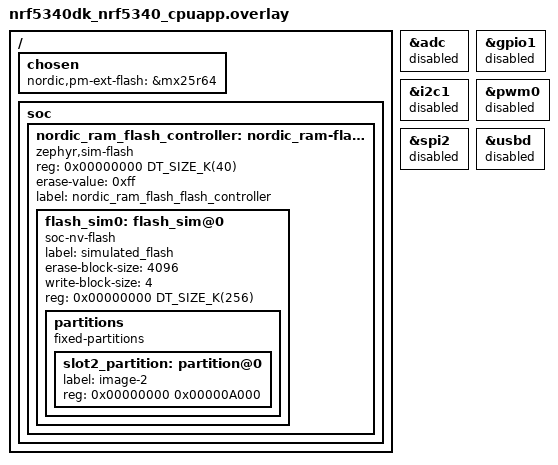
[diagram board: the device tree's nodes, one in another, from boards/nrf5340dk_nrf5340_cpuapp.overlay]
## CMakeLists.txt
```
#
# Copyright (c) 2021 Nordic Semiconductor ASA
#
# SPDX-License-Identifier: LicenseRef-Nordic-5-Clause
#

cmake_minimum_required(VERSION 3.20.0)

if(BOARD STREQUAL "nrf52840dk_nrf52840" OR BOARD STREQUAL "nrf5340dk_nrf5340_cpuapp")
    set(BUILD_WITH_DFU "MATTER" CACHE STRING "Build target with Device Firmware Upgrade support")
else()
    set(BUILD_WITH_DFU "OFF" CACHE STRING "Build target with Device Firmware Upgrade support")
endif()

if(NOT BUILD_WITH_DFU STREQUAL "OFF")
    if(BUILD_WITH_DFU STREQUAL "BLE" AND BOARD STREQUAL "nrf5340dk_nrf5340_cpuapp")
        set(CONF_FILE prj_multi_image_smp_dfu.conf)
    elseif(BUILD_WITH_DFU STREQUAL "BLE")
        set(CONF_FILE prj_single_image_smp_dfu.conf)
    elseif(BUILD_WITH_DFU STREQUAL "MATTER" AND BOARD STREQUAL "nrf5340dk_nrf5340_cpuapp")
        set(CONF_FILE prj_multi_image_matter_dfu.conf)
    elseif(BUILD_WITH_DFU STREQUAL "MATTER")
        set(CONF_FILE prj_single_image_matter_dfu.conf)
    else()
        message(FATAL_ERROR "Selected invalid BUILD_WITH_DFU value: ${BUILD_WITH_DFU}")
    endif()

    if (EXISTS "${CMAKE_CURRENT_SOURCE_DIR}/configuration/${BOARD}/pm_static.yml")
        set(PM_STATIC_YML_FILE ${CMAKE_CURRENT_SOURCE_DIR}/configuration/${BOARD}/pm_static.yml)
    else()
        message(FATAL_ERROR "The ${BOARD} target does not support DFU")
    endif()
endif()

find_package(Zephyr HINTS $ENV{ZEPHYR_BASE})

project(matter-lock)

set(COMMON_ROOT ${ZEPHYR_NRF_MODULE_DIR}/samples/matter/common)
set(NLIO_ROOT ${ZEPHYR_CONNECTEDHOMEIP_MODULE_DIR}/third_party/nlio/repo)
include(${ZEPHYR_CONNECTEDHOMEIP_MODULE_DIR}/config/nrfconnect/app/enable-gnu-std.cmake)
include(${ZEPHYR_CONNECTEDHOMEIP_MODULE_DIR}/src/app/chip_data_model.cmake)

# NORDIC SDK APP START
target_include_directories(app PRIVATE
    src
    ${COMMON_ROOT}/src
    ${NLIO_ROOT}/include
    ${ZEPHYR_CONNECTEDHOMEIP_MODULE_DIR}/zzz_generated/app-common
)

target_sources(app PRIVATE
    src/app_task.cpp
    src/bolt_lock_manager.cpp
    src/main.cpp
    src/zcl_callbacks.cpp
    src/zap-generated/IMClusterCommandHandler.cpp
    src/zap-generated/callback-stub.cpp
    ${COMMON_ROOT}/src/led_widget.cpp
    ${COMMON_ROOT}/src/thread_util.cpp
)

if(BUILD_WITH_DFU STREQUAL "BLE")
    target_sources(app PRIVATE ${COMMON_ROOT}/src/dfu_over_smp.cpp)
endif()

chip_configure_data_model(app
    INCLUDE_SERVER
    ZAP_FILE ${CMAKE_CURRENT_SOURCE_DIR}/src/lock.zap
)
# NORDIC SDK APP END
```

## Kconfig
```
#
# Copyright (c) 2021 Nordic Semiconductor
#
# SPDX-License-Identifier: LicenseRef-Nordic-5-Clause
#

mainmenu "Matter Lock sample application"

config STATE_LEDS
	bool "Use LEDs to indicate the device state"
	default y
	help
	  Use LEDs to render the current state of the device such as the progress of commissioning of
	  the device into a network or the factory reset initiation. Note that setting this option to
	  'n' does not disable the LED indicating the state of the simulated bolt.

source "Kconfig.zephyr"
```

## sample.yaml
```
sample:
  name: Matter Lock
  description: Matter Lock example
tests:
  matter.lock:
    build_only: true
    platform_allow: nrf52840dk_nrf52840 nrf5340dk_nrf5340_cpuapp nrf21540dk_nrf52840
    integration_platforms:
      - nrf52840dk_nrf52840
      - nrf5340dk_nrf5340_cpuapp
      - nrf21540dk_nrf52840
    tags: ci_build
  matter.lock.smp_dfu:
    build_only: true
    platform_allow: nrf52840dk_nrf52840 nrf5340dk_nrf5340_cpuapp
    integration_platforms:
      - nrf52840dk_nrf52840
      - nrf5340dk_nrf5340_cpuapp
    tags: ci_build
    extra_args: "BUILD_WITH_DFU=BLE"
  matter.lock.low_power:
    build_only: true
    platform_allow: nrf52840dk_nrf52840 nrf5340dk_nrf5340_cpuapp
    integration_platforms:
      - nrf52840dk_nrf52840
      - nrf5340dk_nrf5340_cpuapp
    tags: ci_build
    extra_args: "OVERLAY_CONFIG=overlay-low_power.conf"
```

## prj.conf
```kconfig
#
# Copyright (c) 2021 Nordic Semiconductor ASA
#
# SPDX-License-Identifier: LicenseRef-Nordic-5-Clause
#

# Enable CHIP
CONFIG_CHIP=y
CONFIG_CHIP_PROJECT_CONFIG="src/chip_project_config.h"
CONFIG_STD_CPP14=y

# General networking settings
CONFIG_NETWORKING=y
CONFIG_NET_IPV6_NBR_CACHE=n
CONFIG_NET_IPV6_MLD=n
CONFIG_NET_SOCKETS_POLL_MAX=5

# Enable OpenThread MTD
CONFIG_NET_L2_OPENTHREAD=y

CONFIG_OPENTHREAD_MTD=y
CONFIG_OPENTHREAD_FTD=n
CONFIG_OPENTHREAD_SLAAC=y
CONFIG_OPENTHREAD_MTD_NETDIAG=y
CONFIG_OPENTHREAD_MANUAL_START=y
CONFIG_OPENTHREAD_THREAD_STACK_SIZE=6144
CONFIG_OPENTHREAD_NUM_MESSAGE_BUFFERS=64

CONFIG_OPENTHREAD_PANID=4660
CONFIG_OPENTHREAD_CHANNEL=15
CONFIG_OPENTHREAD_NETWORK_NAME="OpenThread"
CONFIG_OPENTHREAD_XPANID="11:11:11:11:22:22:22:22"

# Enable Thread 1.2 features
CONFIG_OPENTHREAD_THREAD_VERSION_1_2=y
CONFIG_OPENTHREAD_DUA=y
CONFIG_OPENTHREAD_MLR=y

# Enable Bluetooth Low Energy
CONFIG_BT=y
CONFIG_BT_PERIPHERAL=y
CONFIG_BT_PERIPHERAL_PREF_MIN_INT=12
CONFIG_BT_PERIPHERAL_PREF_MAX_INT=12
CONFIG_BT_GAP_AUTO_UPDATE_CONN_PARAMS=y
CONFIG_BT_GATT_DYNAMIC_DB=y
CONFIG_BT_DEVICE_APPEARANCE=0
CONFIG_BT_DEVICE_NAME_DYNAMIC=y
CONFIG_BT_DEVICE_NAME_MAX=15
CONFIG_BT_DEVICE_NAME="MatterLock"
CONFIG_BT_MAX_CONN=1
CONFIG_BT_L2CAP_TX_MTU=247
CONFIG_BT_BUF_ACL_RX_SIZE=251
CONFIG_BT_BUF_ACL_TX_SIZE=251

# Use NFC to share commissioning information
CONFIG_CHIP_NFC_COMMISSIONING=y

# Use nrf_security
CONFIG_OPENTHREAD_NRF_SECURITY_CHOICE=y

CONFIG_CC3XX_BACKEND=n
CONFIG_OBERON_BACKEND=y

CONFIG_MBEDTLS_ENABLE_HEAP=y
CONFIG_MBEDTLS_HEAP_SIZE=15360
CONFIG_MBEDTLS_TLS_LIBRARY=y
CONFIG_NRF_SECURITY_ADVANCED=y

CONFIG_MBEDTLS_AES_C=y
CONFIG_MBEDTLS_ECP_C=y
CONFIG_MBEDTLS_ECP_DP_SECP256R1_ENABLED=y
CONFIG_MBEDTLS_CTR_DRBG_C=y
CONFIG_MBEDTLS_CIPHER_MODE_CTR=y
CONFIG_MBEDTLS_ECJPAKE_C=y
CONFIG_MBEDTLS_SHA256_C=y
CONFIG_MBEDTLS_PK_C=y
CONFIG_MBEDTLS_PK_WRITE_C=y
CONFIG_MBEDTLS_X509_CREATE_C=y
CONFIG_MBEDTLS_X509_CSR_WRITE_C=y

# Disable unneeded crypto operations
CONFIG_MBEDTLS_SHA384_C=n
CONFIG_MBEDTLS_SHA512_C=n
CONFIG_MBEDTLS_CIPHER_MODE_XTS=n
CONFIG_MBEDTLS_CHACHA20_C=n
CONFIG_MBEDTLS_POLY1305_C=n
CONFIG_MBEDTLS_CHACHAPOLY_C=n
CONFIG_MBEDTLS_GCM_C=n
CONFIG_MBEDTLS_RSA_C=n

# Add support for LEDs and buttons on Nordic development kits
CONFIG_DK_LIBRARY=y

# Other settings
CONFIG_LOG=y
CONFIG_LOG_MODE_MINIMAL=y
CONFIG_MATTER_LOG_LEVEL_DBG=y
CONFIG_PRINTK_SYNC=y
CONFIG_MAIN_STACK_SIZE=8192
CONFIG_INIT_STACKS=y
CONFIG_HW_STACK_PROTECTION=y
CONFIG_HWINFO=y
CONFIG_THREAD_NAME=y
CONFIG_SHELL=y
CONFIG_ASSERT=y
```

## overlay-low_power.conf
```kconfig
#
# Copyright (c) 2021 Nordic Semiconductor
#
# SPDX-License-Identifier: LicenseRef-Nordic-5-Clause
#

# Enable MTD Sleepy End Device
CONFIG_CHIP_ENABLE_SLEEPY_END_DEVICE_SUPPORT=y

# SED requires less aggresive BLE connection intervals
CONFIG_BT_PERIPHERAL_PREF_MIN_INT=36
CONFIG_BT_PERIPHERAL_PREF_MAX_INT=36

# Disable UART console
CONFIG_SHELL=n
CONFIG_LOG=n
CONFIG_UART_CONSOLE=n
CONFIG_SERIAL=n

# Suspend devices when the CPU goes into sleep
CONFIG_PM_DEVICE=y

# Disable auxiliary state LEDs
CONFIG_STATE_LEDS=n
```

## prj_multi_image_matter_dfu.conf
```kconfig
#
# Copyright (c) 2022 Nordic Semiconductor ASA
#
# SPDX-License-Identifier: LicenseRef-Nordic-5-Clause
#

# Enable CHIP
CONFIG_CHIP=y
CONFIG_CHIP_PROJECT_CONFIG="src/chip_project_config.h"
CONFIG_STD_CPP14=y

# General networking settings
CONFIG_NETWORKING=y
CONFIG_NET_IPV6_NBR_CACHE=n
CONFIG_NET_IPV6_MLD=n
CONFIG_NET_SOCKETS_POLL_MAX=5

# Enable OpenThread MTD
CONFIG_NET_L2_OPENTHREAD=y

CONFIG_OPENTHREAD_MTD=y
CONFIG_OPENTHREAD_FTD=n
CONFIG_OPENTHREAD_SLAAC=y
CONFIG_OPENTHREAD_MTD_NETDIAG=y
CONFIG_OPENTHREAD_MANUAL_START=y
CONFIG_OPENTHREAD_THREAD_STACK_SIZE=6144
CONFIG_OPENTHREAD_NUM_MESSAGE_BUFFERS=64

CONFIG_OPENTHREAD_PANID=4660
CONFIG_OPENTHREAD_CHANNEL=15
CONFIG_OPENTHREAD_NETWORK_NAME="OpenThread"
CONFIG_OPENTHREAD_XPANID="11:11:11:11:22:22:22:22"

# Enable Thread 1.2 features
CONFIG_OPENTHREAD_THREAD_VERSION_1_2=y
CONFIG_OPENTHREAD_DUA=y
CONFIG_OPENTHREAD_MLR=y

# Enable Bluetooth Low Energy
CONFIG_BT=y
CONFIG_BT_PERIPHERAL=y
CONFIG_BT_PERIPHERAL_PREF_MIN_INT=12
CONFIG_BT_PERIPHERAL_PREF_MAX_INT=12
CONFIG_BT_GAP_AUTO_UPDATE_CONN_PARAMS=y
CONFIG_BT_GATT_DYNAMIC_DB=y
CONFIG_BT_DEVICE_APPEARANCE=0
CONFIG_BT_DEVICE_NAME_DYNAMIC=y
CONFIG_BT_DEVICE_NAME_MAX=15
CONFIG_BT_DEVICE_NAME="MatterLock"
CONFIG_BT_MAX_CONN=1
CONFIG_BT_L2CAP_TX_MTU=247
CONFIG_BT_BUF_ACL_RX_SIZE=251
CONFIG_BT_BUF_ACL_TX_SIZE=251

# Use NFC to share commissioning information
CONFIG_CHIP_NFC_COMMISSIONING=y

# Use nrf_security
CONFIG_OPENTHREAD_NRF_SECURITY_CHOICE=y

CONFIG_CC3XX_BACKEND=n
CONFIG_OBERON_BACKEND=y

CONFIG_MBEDTLS_ENABLE_HEAP=y
CONFIG_MBEDTLS_HEAP_SIZE=15360
CONFIG_MBEDTLS_TLS_LIBRARY=y
CONFIG_NRF_SECURITY_ADVANCED=y

CONFIG_MBEDTLS_AES_C=y
CONFIG_MBEDTLS_ECP_C=y
CONFIG_MBEDTLS_ECP_DP_SECP256R1_ENABLED=y
CONFIG_MBEDTLS_CTR_DRBG_C=y
CONFIG_MBEDTLS_CIPHER_MODE_CTR=y
CONFIG_MBEDTLS_ECJPAKE_C=y
CONFIG_MBEDTLS_SHA256_C=y
CONFIG_MBEDTLS_PK_C=y
CONFIG_MBEDTLS_PK_WRITE_C=y
CONFIG_MBEDTLS_X509_CREATE_C=y
CONFIG_MBEDTLS_X509_CSR_WRITE_C=y

# Disable unneeded crypto operations
CONFIG_MBEDTLS_SHA384_C=n
CONFIG_MBEDTLS_SHA512_C=n
CONFIG_MBEDTLS_CIPHER_MODE_XTS=n
CONFIG_MBEDTLS_CHACHA20_C=n
CONFIG_MBEDTLS_POLY1305_C=n
CONFIG_MBEDTLS_CHACHAPOLY_C=n
CONFIG_MBEDTLS_GCM_C=n
CONFIG_MBEDTLS_RSA_C=n

# Add support for LEDs and buttons on Nordic development kits
CONFIG_DK_LIBRARY=y

# Other settings
CONFIG_LOG=y
CONFIG_LOG_MODE_MINIMAL=y
CONFIG_MATTER_LOG_LEVEL_DBG=y
CONFIG_PRINTK_SYNC=y
CONFIG_MAIN_STACK_SIZE=8192
CONFIG_INIT_STACKS=y
CONFIG_HW_STACK_PROTECTION=y
CONFIG_HWINFO=y
CONFIG_THREAD_NAME=y
CONFIG_SHELL=y
CONFIG_ASSERT=y

# Enable bootloader and DFU related configs
CONFIG_BOOTLOADER_MCUBOOT=y
CONFIG_UPDATEABLE_IMAGE_NUMBER=2

# QSPI configuration
CONFIG_NORDIC_QSPI_NOR=y
CONFIG_NORDIC_QSPI_NOR_FLASH_LAYOUT_PAGE_SIZE=4096
CONFIG_NORDIC_QSPI_NOR_STACK_WRITE_BUFFER_SIZE=16

# FLASH nop device is needed to access network core image data.
CONFIG_FLASH_NOP_DEVICE=y

# Enable Matter OTA
CONFIG_CHIP_OTA_REQUESTOR=y
CONFIG_IMG_MANAGER=y
```

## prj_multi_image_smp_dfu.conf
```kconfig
#
# Copyright (c) 2021 Nordic Semiconductor ASA
#
# SPDX-License-Identifier: LicenseRef-Nordic-5-Clause
#

# Enable CHIP
CONFIG_CHIP=y
CONFIG_CHIP_PROJECT_CONFIG="src/chip_project_config.h"
CONFIG_STD_CPP14=y

# General networking settings
CONFIG_NETWORKING=y
CONFIG_NET_IPV6_NBR_CACHE=n
CONFIG_NET_IPV6_MLD=n
CONFIG_NET_SOCKETS_POLL_MAX=5

# Enable OpenThread MTD
CONFIG_NET_L2_OPENTHREAD=y

CONFIG_OPENTHREAD_MTD=y
CONFIG_OPENTHREAD_FTD=n
CONFIG_OPENTHREAD_SLAAC=y
CONFIG_OPENTHREAD_MTD_NETDIAG=y
CONFIG_OPENTHREAD_MANUAL_START=y
CONFIG_OPENTHREAD_THREAD_STACK_SIZE=6144
CONFIG_OPENTHREAD_NUM_MESSAGE_BUFFERS=64

CONFIG_OPENTHREAD_PANID=4660
CONFIG_OPENTHREAD_CHANNEL=15
CONFIG_OPENTHREAD_NETWORK_NAME="OpenThread"
CONFIG_OPENTHREAD_XPANID="11:11:11:11:22:22:22:22"

# Enable Thread 1.2 features
CONFIG_OPENTHREAD_THREAD_VERSION_1_2=y
CONFIG_OPENTHREAD_DUA=y
CONFIG_OPENTHREAD_MLR=y

# Enable Bluetooth Low Energy
CONFIG_BT=y
CONFIG_BT_PERIPHERAL=y
CONFIG_BT_PERIPHERAL_PREF_MIN_INT=12
CONFIG_BT_PERIPHERAL_PREF_MAX_INT=12
CONFIG_BT_GAP_AUTO_UPDATE_CONN_PARAMS=y
CONFIG_BT_GATT_DYNAMIC_DB=y
CONFIG_BT_DEVICE_APPEARANCE=0
CONFIG_BT_DEVICE_NAME_DYNAMIC=y
CONFIG_BT_DEVICE_NAME_MAX=15
CONFIG_BT_DEVICE_NAME="MatterLock"
CONFIG_BT_MAX_CONN=1

# Use NFC to share commissioning information
CONFIG_CHIP_NFC_COMMISSIONING=y

# Use nrf_security
CONFIG_OPENTHREAD_NRF_SECURITY_CHOICE=y

CONFIG_CC3XX_BACKEND=n
CONFIG_OBERON_BACKEND=y

CONFIG_MBEDTLS_ENABLE_HEAP=y
CONFIG_MBEDTLS_HEAP_SIZE=15360
CONFIG_MBEDTLS_TLS_LIBRARY=y
CONFIG_NRF_SECURITY_ADVANCED=y

CONFIG_MBEDTLS_AES_C=y
CONFIG_MBEDTLS_ECP_C=y
CONFIG_MBEDTLS_ECP_DP_SECP256R1_ENABLED=y
CONFIG_MBEDTLS_CTR_DRBG_C=y
CONFIG_MBEDTLS_CIPHER_MODE_CTR=y
CONFIG_MBEDTLS_ECJPAKE_C=y
CONFIG_MBEDTLS_SHA256_C=y
CONFIG_MBEDTLS_PK_C=y
CONFIG_MBEDTLS_PK_WRITE_C=y
CONFIG_MBEDTLS_X509_CREATE_C=y
CONFIG_MBEDTLS_X509_CSR_WRITE_C=y

# Disable unneeded crypto operations
CONFIG_MBEDTLS_SHA384_C=n
CONFIG_MBEDTLS_SHA512_C=n
CONFIG_MBEDTLS_CIPHER_MODE_XTS=n
CONFIG_MBEDTLS_CHACHA20_C=n
CONFIG_MBEDTLS_POLY1305_C=n
CONFIG_MBEDTLS_CHACHAPOLY_C=n
CONFIG_MBEDTLS_GCM_C=n
CONFIG_MBEDTLS_RSA_C=n

# Add support for LEDs and buttons on Nordic development kits
CONFIG_DK_LIBRARY=y

# Other settings
CONFIG_LOG=y
CONFIG_LOG_MODE_MINIMAL=y
CONFIG_MATTER_LOG_LEVEL_DBG=y
CONFIG_PRINTK_SYNC=y
CONFIG_MAIN_STACK_SIZE=8192
CONFIG_INIT_STACKS=y
CONFIG_HW_STACK_PROTECTION=y
CONFIG_HWINFO=y
CONFIG_THREAD_NAME=y
CONFIG_SHELL=y
CONFIG_ASSERT=y

# Enable bootloader and DFU related configs
CONFIG_BOOTLOADER_MCUBOOT=y
CONFIG_UPDATEABLE_IMAGE_NUMBER=2

# QSPI configuration
CONFIG_NORDIC_QSPI_NOR=y
CONFIG_NORDIC_QSPI_NOR_FLASH_LAYOUT_PAGE_SIZE=4096
CONFIG_NORDIC_QSPI_NOR_STACK_WRITE_BUFFER_SIZE=16

# MCU Manager and SMP configuration
CONFIG_MCUMGR=y
CONFIG_MCUMGR_CMD_IMG_MGMT=y
CONFIG_MCUMGR_CMD_OS_MGMT=y
CONFIG_MCUMGR_SMP_BT=y
CONFIG_MCUMGR_SMP_BT_AUTHEN=n
CONFIG_MCUMGR_BUF_COUNT=6

# Increase BT MTU and RX buffer for big size DFU messages
CONFIG_BT_L2CAP_TX_MTU=498
CONFIG_BT_BUF_ACL_TX_SIZE=251
CONFIG_BT_BUF_ACL_RX_SIZE=502

# Increase max number of pending GATT notification callbacks
CONFIG_BT_CONN_TX_MAX=6

# Increase system workqueue size, as SMP is processed within it
CONFIG_SYSTEM_WORKQUEUE_STACK_SIZE=2800

# FLASH nop device is enabled to prevent bus faults when mcumgr tries to access
# simulated partition with network core image data.
CONFIG_FLASH_NOP_DEVICE=y

# Enable custom SMP request to erase settings partition.
CONFIG_MCUMGR_GRP_ZEPHYR_BASIC=y
CONFIG_MCUMGR_GRP_BASIC_CMD_STORAGE_ERASE=y

# Enable Matter OTA
CONFIG_CHIP_OTA_REQUESTOR=y
```

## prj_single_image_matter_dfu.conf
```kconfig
#
# Copyright (c) 2022 Nordic Semiconductor ASA
#
# SPDX-License-Identifier: LicenseRef-Nordic-5-Clause
#

# Enable CHIP
CONFIG_CHIP=y
CONFIG_CHIP_PROJECT_CONFIG="src/chip_project_config.h"
CONFIG_STD_CPP14=y

# General networking settings
CONFIG_NETWORKING=y
CONFIG_NET_IPV6_NBR_CACHE=n
CONFIG_NET_IPV6_MLD=n
CONFIG_NET_SOCKETS_POLL_MAX=5

# Enable OpenThread MTD
CONFIG_NET_L2_OPENTHREAD=y

CONFIG_OPENTHREAD_MTD=y
CONFIG_OPENTHREAD_FTD=n
CONFIG_OPENTHREAD_SLAAC=y
CONFIG_OPENTHREAD_MTD_NETDIAG=y
CONFIG_OPENTHREAD_MANUAL_START=y
CONFIG_OPENTHREAD_THREAD_STACK_SIZE=6144
CONFIG_OPENTHREAD_NUM_MESSAGE_BUFFERS=64

CONFIG_OPENTHREAD_PANID=4660
CONFIG_OPENTHREAD_CHANNEL=15
CONFIG_OPENTHREAD_NETWORK_NAME="OpenThread"
CONFIG_OPENTHREAD_XPANID="11:11:11:11:22:22:22:22"

# Enable Thread 1.2 features
CONFIG_OPENTHREAD_THREAD_VERSION_1_2=y
CONFIG_OPENTHREAD_DUA=y
CONFIG_OPENTHREAD_MLR=y

# Enable Bluetooth Low Energy
CONFIG_BT=y
CONFIG_BT_PERIPHERAL=y
CONFIG_BT_PERIPHERAL_PREF_MIN_INT=12
CONFIG_BT_PERIPHERAL_PREF_MAX_INT=12
CONFIG_BT_GAP_AUTO_UPDATE_CONN_PARAMS=y
CONFIG_BT_GATT_DYNAMIC_DB=y
CONFIG_BT_DEVICE_APPEARANCE=0
CONFIG_BT_DEVICE_NAME_DYNAMIC=y
CONFIG_BT_DEVICE_NAME_MAX=15
CONFIG_BT_DEVICE_NAME="MatterLock"
CONFIG_BT_MAX_CONN=1
CONFIG_BT_L2CAP_TX_MTU=247
CONFIG_BT_BUF_ACL_RX_SIZE=251
CONFIG_BT_BUF_ACL_TX_SIZE=251

# Use NFC to share commissioning information
CONFIG_CHIP_NFC_COMMISSIONING=y

# Use nrf_security
CONFIG_OPENTHREAD_NRF_SECURITY_CHOICE=y

CONFIG_CC3XX_BACKEND=n
CONFIG_OBERON_BACKEND=y

CONFIG_MBEDTLS_ENABLE_HEAP=y
CONFIG_MBEDTLS_HEAP_SIZE=15360
CONFIG_MBEDTLS_TLS_LIBRARY=y
CONFIG_NRF_SECURITY_ADVANCED=y

CONFIG_MBEDTLS_AES_C=y
CONFIG_MBEDTLS_ECP_C=y
CONFIG_MBEDTLS_ECP_DP_SECP256R1_ENABLED=y
CONFIG_MBEDTLS_CTR_DRBG_C=y
CONFIG_MBEDTLS_CIPHER_MODE_CTR=y
CONFIG_MBEDTLS_ECJPAKE_C=y
CONFIG_MBEDTLS_SHA256_C=y
CONFIG_MBEDTLS_PK_C=y
CONFIG_MBEDTLS_PK_WRITE_C=y
CONFIG_MBEDTLS_X509_CREATE_C=y
CONFIG_MBEDTLS_X509_CSR_WRITE_C=y

# Disable unneeded crypto operations
CONFIG_MBEDTLS_SHA384_C=n
CONFIG_MBEDTLS_SHA512_C=n
CONFIG_MBEDTLS_CIPHER_MODE_XTS=n
CONFIG_MBEDTLS_CHACHA20_C=n
CONFIG_MBEDTLS_POLY1305_C=n
CONFIG_MBEDTLS_CHACHAPOLY_C=n
CONFIG_MBEDTLS_GCM_C=n
CONFIG_MBEDTLS_RSA_C=n

# Add support for LEDs and buttons on Nordic development kits
CONFIG_DK_LIBRARY=y

# Other settings
CONFIG_LOG=y
CONFIG_LOG_MODE_MINIMAL=y
CONFIG_MATTER_LOG_LEVEL_DBG=y
CONFIG_PRINTK_SYNC=y
CONFIG_MAIN_STACK_SIZE=8192
CONFIG_INIT_STACKS=y
CONFIG_HW_STACK_PROTECTION=y
CONFIG_HWINFO=y
CONFIG_THREAD_NAME=y
CONFIG_SHELL=y
CONFIG_ASSERT=y

# Enable bootloader and DFU related configs
CONFIG_BOOTLOADER_MCUBOOT=y

# QSPI configuration
CONFIG_NORDIC_QSPI_NOR=y
CONFIG_NORDIC_QSPI_NOR_FLASH_LAYOUT_PAGE_SIZE=4096
CONFIG_NORDIC_QSPI_NOR_STACK_WRITE_BUFFER_SIZE=16

# Enable Matter OTA
CONFIG_CHIP_OTA_REQUESTOR=y
CONFIG_IMG_MANAGER=y
```

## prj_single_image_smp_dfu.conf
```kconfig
#
# Copyright (c) 2021 Nordic Semiconductor ASA
#
# SPDX-License-Identifier: LicenseRef-Nordic-5-Clause
#

# Enable CHIP
CONFIG_CHIP=y
CONFIG_CHIP_PROJECT_CONFIG="src/chip_project_config.h"
CONFIG_STD_CPP14=y

# General networking settings
CONFIG_NETWORKING=y
CONFIG_NET_IPV6_NBR_CACHE=n
CONFIG_NET_IPV6_MLD=n
CONFIG_NET_SOCKETS_POLL_MAX=5

# Enable OpenThread MTD
CONFIG_NET_L2_OPENTHREAD=y

CONFIG_OPENTHREAD_MTD=y
CONFIG_OPENTHREAD_FTD=n
CONFIG_OPENTHREAD_SLAAC=y
CONFIG_OPENTHREAD_MTD_NETDIAG=y
CONFIG_OPENTHREAD_MANUAL_START=y
CONFIG_OPENTHREAD_THREAD_STACK_SIZE=6144
CONFIG_OPENTHREAD_NUM_MESSAGE_BUFFERS=64

CONFIG_OPENTHREAD_PANID=4660
CONFIG_OPENTHREAD_CHANNEL=15
CONFIG_OPENTHREAD_NETWORK_NAME="OpenThread"
CONFIG_OPENTHREAD_XPANID="11:11:11:11:22:22:22:22"

# Enable Thread 1.2 features
CONFIG_OPENTHREAD_THREAD_VERSION_1_2=y
CONFIG_OPENTHREAD_DUA=y
CONFIG_OPENTHREAD_MLR=y

# Enable Bluetooth Low Energy
CONFIG_BT=y
CONFIG_BT_PERIPHERAL=y
CONFIG_BT_PERIPHERAL_PREF_MIN_INT=12
CONFIG_BT_PERIPHERAL_PREF_MAX_INT=12
CONFIG_BT_GAP_AUTO_UPDATE_CONN_PARAMS=y
CONFIG_BT_GATT_DYNAMIC_DB=y
CONFIG_BT_DEVICE_APPEARANCE=0
CONFIG_BT_DEVICE_NAME_DYNAMIC=y
CONFIG_BT_DEVICE_NAME_MAX=15
CONFIG_BT_DEVICE_NAME="MatterLock"
CONFIG_BT_MAX_CONN=1

# Use NFC to share commissioning information
CONFIG_CHIP_NFC_COMMISSIONING=y

# Use nrf_security
CONFIG_OPENTHREAD_NRF_SECURITY_CHOICE=y

CONFIG_CC3XX_BACKEND=n
CONFIG_OBERON_BACKEND=y

CONFIG_MBEDTLS_ENABLE_HEAP=y
CONFIG_MBEDTLS_HEAP_SIZE=15360
CONFIG_MBEDTLS_TLS_LIBRARY=y
CONFIG_NRF_SECURITY_ADVANCED=y

CONFIG_MBEDTLS_AES_C=y
CONFIG_MBEDTLS_ECP_C=y
CONFIG_MBEDTLS_ECP_DP_SECP256R1_ENABLED=y
CONFIG_MBEDTLS_CTR_DRBG_C=y
CONFIG_MBEDTLS_CIPHER_MODE_CTR=y
CONFIG_MBEDTLS_ECJPAKE_C=y
CONFIG_MBEDTLS_SHA256_C=y
CONFIG_MBEDTLS_PK_C=y
CONFIG_MBEDTLS_PK_WRITE_C=y
CONFIG_MBEDTLS_X509_CREATE_C=y
CONFIG_MBEDTLS_X509_CSR_WRITE_C=y

# Disable unneeded crypto operations
CONFIG_MBEDTLS_SHA384_C=n
CONFIG_MBEDTLS_SHA512_C=n
CONFIG_MBEDTLS_CIPHER_MODE_XTS=n
CONFIG_MBEDTLS_CHACHA20_C=n
CONFIG_MBEDTLS_POLY1305_C=n
CONFIG_MBEDTLS_CHACHAPOLY_C=n
CONFIG_MBEDTLS_GCM_C=n
CONFIG_MBEDTLS_RSA_C=n

# Add support for LEDs and buttons on Nordic development kits
CONFIG_DK_LIBRARY=y

# Other settings
CONFIG_LOG=y
CONFIG_LOG_MODE_MINIMAL=y
CONFIG_MATTER_LOG_LEVEL_DBG=y
CONFIG_PRINTK_SYNC=y
CONFIG_MAIN_STACK_SIZE=8192
CONFIG_INIT_STACKS=y
CONFIG_HW_STACK_PROTECTION=y
CONFIG_HWINFO=y
CONFIG_THREAD_NAME=y
CONFIG_SHELL=y
CONFIG_ASSERT=y

# Enable bootloader and DFU related configs
CONFIG_BOOTLOADER_MCUBOOT=y

# QSPI configuration
CONFIG_NORDIC_QSPI_NOR=y
CONFIG_NORDIC_QSPI_NOR_FLASH_LAYOUT_PAGE_SIZE=4096
CONFIG_NORDIC_QSPI_NOR_STACK_WRITE_BUFFER_SIZE=16

# MCU Manager and SMP configuration
CONFIG_MCUMGR=y
CONFIG_MCUMGR_CMD_IMG_MGMT=y
CONFIG_MCUMGR_CMD_OS_MGMT=y
CONFIG_MCUMGR_SMP_BT=y
CONFIG_MCUMGR_SMP_BT_AUTHEN=n
CONFIG_MCUMGR_BUF_COUNT=6

# Increase BT MTU and RX buffer for big size DFU messages
CONFIG_BT_L2CAP_TX_MTU=498
CONFIG_BT_BUF_ACL_TX_SIZE=251
CONFIG_BT_BUF_ACL_RX_SIZE=502

# Increase max number of pending GATT notification callbacks
CONFIG_BT_CONN_TX_MAX=6

# Increase MCUMGR_BUF_SIZE, as it must be big enough to fit MAX MTU + overhead and for single-image DFU default is 384 B
CONFIG_MCUMGR_BUF_SIZE=1024

# Increase system workqueue size, as SMP is processed within it
CONFIG_SYSTEM_WORKQUEUE_STACK_SIZE=2800

# Enable Matter OTA
CONFIG_CHIP_OTA_REQUESTOR=y
```

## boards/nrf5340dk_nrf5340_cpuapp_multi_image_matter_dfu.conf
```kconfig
#
# Copyright (c) 2022 Nordic Semiconductor ASA
#
# SPDX-License-Identifier: LicenseRef-Nordic-5-Clause
#

# Generate random numbers using Xoroshiro algorithm instead of direct calls
# to the cryptocell library to workaround firmware hangs.
CONFIG_XOROSHIRO_RANDOM_GENERATOR=y
```

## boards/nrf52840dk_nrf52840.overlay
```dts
/* Copyright (c) 2021 Nordic Semiconductor ASA
 *
 * SPDX-License-Identifier: LicenseRef-Nordic-5-Clause
 */

/ {
	chosen {
		nordic,pm-ext-flash = &mx25r64;
	};
};


/ {
	/*
	* In some default configurations within the nRF Connect SDK,
	* e.g. on nRF52840, the chosen zephyr,entropy node is &cryptocell.
	* This devicetree overlay ensures that default is overridden wherever it
	* is set, as this application uses the RNG node for entropy exclusively.
	*/
	chosen {
		zephyr,entropy = &rng;
	};
};

/* Disable unused peripherals to reduce power consumption */
&adc {
	status = "disabled";
};
&uart1 {
	status = "disabled";
};
&gpio1 {
	status = "disabled";
};
&i2c0 {
	status = "disabled";
};
&pwm0 {
	status = "disabled";
};
&spi1 {
	status = "disabled";
};
&spi3 {
	status = "disabled";
};
&usbd {
	status = "disabled";
};
```

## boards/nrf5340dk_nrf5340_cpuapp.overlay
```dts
/*
 * Copyright (c) 2021 Nordic Semiconductor ASA
 *
 * SPDX-License-Identifier: LicenseRef-Nordic-5-Clause
 */

/ {
	chosen {
		nordic,pm-ext-flash = &mx25r64;
	};

	soc {
		/* Add a flash controller which has the compatible
		 * 'zephyr,sim-flash'. This will ensure that the flash
		 * simulator can use it. None of the other properties in this
		 * node is used for anything.
		 */
		nordic_ram_flash_controller: nordic_ram-flash-controller@0 {
			compatible = "zephyr,sim-flash";
			reg = <0x00000000 DT_SIZE_K(40)>;
			#address-cells = <1>;
			#size-cells = <1>;
			erase-value = <0xff>;
			label = "nordic_ram_flash_flash_controller";

			/* This node label must match that used in the flash
			 * simulator.
			 */
			flash_sim0: flash_sim@0 {
				status = "okay";
				compatible = "soc-nv-flash";
				label = "simulated_flash";
				erase-block-size = <4096>;
				write-block-size = <4>;
				reg = <0x00000000 DT_SIZE_K(256)>;

				partitions {
					compatible = "fixed-partitions";
					#address-cells = <1>;
					#size-cells = <1>;

					/* This partition must be defined for
					 * MCUboot to find the partition ID
					 * of the primary slot for image 1,
					 * which is stored in this partition.
					 */
					slot2_partition: partition@0 {
						label = "image-2";
						reg = <0x00000000 0x00000A000>;
					};
				};
			};
		};
	};
};

/* Disable unused peripherals to reduce power consumption */
&adc {
	status = "disabled";
};
&gpio1 {
	status = "disabled";
};
&i2c1 {
	status = "disabled";
};
&pwm0 {
	status = "disabled";
};
&spi2 {
	status = "disabled";
};
&usbd {
	status = "disabled";
};
```

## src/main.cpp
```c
/*
 * Copyright (c) 2021 Nordic Semiconductor ASA
 *
 * SPDX-License-Identifier: LicenseRef-Nordic-5-Clause
 */

#include "app_task.h"

#include <logging/log.h>

#include <lib/support/CHIPMem.h>
#include <platform/CHIPDeviceLayer.h>

LOG_MODULE_REGISTER(app);

using namespace ::chip::DeviceLayer;

int main()
{
	int ret = 0;
	CHIP_ERROR err = CHIP_NO_ERROR;

	err = chip::Platform::MemoryInit();
	if (err != CHIP_NO_ERROR) {
		LOG_ERR("Platform::MemoryInit() failed");
		goto exit;
	}

	LOG_INF("Init CHIP stack");
	err = PlatformMgr().InitChipStack();
	if (err != CHIP_NO_ERROR) {
		LOG_ERR("PlatformMgr().InitChipStack() failed");
		goto exit;
	}

	LOG_INF("Starting CHIP task");
	err = PlatformMgr().StartEventLoopTask();
	if (err != CHIP_NO_ERROR) {
		LOG_ERR("PlatformMgr().StartEventLoopTask() failed");
		goto exit;
	}

	LOG_INF("Init Thread stack");
	err = ThreadStackMgr().InitThreadStack();
	if (err != CHIP_NO_ERROR) {
		LOG_ERR("ThreadStackMgr().InitThreadStack() failed");
		goto exit;
	}

#ifdef CONFIG_OPENTHREAD_MTD_SED
	err = ConnectivityMgr().SetThreadDeviceType(ConnectivityManager::kThreadDeviceType_SleepyEndDevice);
#else
	err = ConnectivityMgr().SetThreadDeviceType(ConnectivityManager::kThreadDeviceType_MinimalEndDevice);
#endif
	if (err != CHIP_NO_ERROR) {
		LOG_ERR("ConnectivityMgr().SetThreadDeviceType() failed");
		goto exit;
	}

	ret = GetAppTask().StartApp();
	if (ret != 0) {
		err = chip::System::MapErrorZephyr(ret);
	}

exit:
	return err == CHIP_NO_ERROR ? EXIT_SUCCESS : EXIT_FAILURE;
}
```

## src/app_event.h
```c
/*
 * Copyright (c) 2021 Nordic Semiconductor ASA
 *
 * SPDX-License-Identifier: LicenseRef-Nordic-5-Clause
 */

#pragma once

#include <cstdint>

#include "led_widget.h"

struct AppEvent {
	enum LockEventType : uint8_t { Lock, Unlock, Toggle, CompleteLockAction };

	enum FunctionEventType : uint8_t { FunctionPress = CompleteLockAction + 1, FunctionRelease, FunctionTimer };

	enum UpdateLedStateEventType : uint8_t { UpdateLedState = FunctionTimer + 1 };

	enum OtherEventType : uint8_t {
		StartThread = UpdateLedState + 1,
		StartBleAdvertising,
#ifdef CONFIG_MCUMGR_SMP_BT
		StartSMPAdvertising
#endif
	};

	AppEvent() = default;
	AppEvent(LockEventType type, bool chipInitiated) : Type(type), LockEvent{ chipInitiated } {}
	explicit AppEvent(FunctionEventType type) : Type(type) {}
	AppEvent(UpdateLedStateEventType type, LEDWidget *ledWidget) : Type(type), UpdateLedStateEvent{ ledWidget } {}
	explicit AppEvent(OtherEventType type) : Type(type) {}

	uint8_t Type;

	union {
		struct { /* was the event triggered by CHIP Data Model layer */
			bool ChipInitiated;
		} LockEvent;
		struct {
			LEDWidget *LedWidget;
		} UpdateLedStateEvent;
	};
};
```

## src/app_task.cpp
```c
/*
 * Copyright (c) 2021 Nordic Semiconductor ASA
 *
 * SPDX-License-Identifier: LicenseRef-Nordic-5-Clause
 */

#include "app_task.h"

#include "bolt_lock_manager.h"
#include "led_widget.h"
#include "thread_util.h"

#include <platform/CHIPDeviceLayer.h>

#include <app-common/zap-generated/attribute-id.h>
#include <app-common/zap-generated/attribute-type.h>
#include <app-common/zap-generated/attributes/Accessors.h>
#include <app-common/zap-generated/cluster-id.h>
#include <app/server/OnboardingCodesUtil.h>
#include <app/server/Server.h>
#include <credentials/DeviceAttestationCredsProvider.h>
#include <credentials/examples/DeviceAttestationCredsExample.h>

#ifdef CONFIG_CHIP_OTA_REQUESTOR
#include <app/clusters/ota-requestor/BDXDownloader.h>
#include <app/clusters/ota-requestor/OTARequestor.h>
#include <platform/GenericOTARequestorDriver.h>
#include <platform/nrfconnect/OTAImageProcessorImpl.h>
#endif

#include <dk_buttons_and_leds.h>
#include <logging/log.h>
#include <zephyr.h>

#include <algorithm>

using namespace ::chip;
using namespace ::chip::app;
using namespace ::chip::Credentials;
using namespace ::chip::DeviceLayer;

LOG_MODULE_DECLARE(app);

namespace
{
constexpr size_t kAppEventQueueSize = 10;
constexpr uint32_t kFactoryResetTriggerTimeout = 3000;
constexpr uint32_t kFactoryResetCancelWindow = 3000;
constexpr EndpointId kLockEndpointId = 1;

K_MSGQ_DEFINE(sAppEventQueue, sizeof(AppEvent), kAppEventQueueSize, alignof(AppEvent));
LEDWidget sStatusLED;
LEDWidget sLockLED;
LEDWidget sUnusedLED;
LEDWidget sUnusedLED_1;

bool sIsThreadProvisioned;
bool sIsThreadEnabled;
bool sHaveBLEConnections;

k_timer sFunctionTimer;

#ifdef CONFIG_CHIP_OTA_REQUESTOR
GenericOTARequestorDriver sOTARequestorDriver;
OTAImageProcessorImpl sOTAImageProcessor;
chip::BDXDownloader sBDXDownloader;
chip::OTARequestor sOTARequestor;
#endif
} /* namespace */

AppTask AppTask::sAppTask;

int AppTask::Init()
{
	/* Initialize LEDs */
	LEDWidget::InitGpio();
	LEDWidget::SetStateUpdateCallback(LEDStateUpdateHandler);

	sStatusLED.Init(DK_LED1);
	sLockLED.Init(DK_LED2);
	sLockLED.Set(!BoltLockMgr().IsUnlocked());
	sUnusedLED.Init(DK_LED3);
	sUnusedLED_1.Init(DK_LED4);

	UpdateStatusLED();

	/* Initialize buttons */
	int ret = dk_buttons_init(ButtonEventHandler);
	if (ret) {
		LOG_ERR("dk_buttons_init() failed");
		return ret;
	}

#ifdef CONFIG_MCUMGR_SMP_BT
	GetDFUOverSMP().Init(RequestSMPAdvertisingStart);
	GetDFUOverSMP().ConfirmNewImage();
#endif

	/* Initialize function timer */
	k_timer_init(&sFunctionTimer, &AppTask::TimerEventHandler, nullptr);
	k_timer_user_data_set(&sFunctionTimer, this);

	/* Initialize lock manager */
	BoltLockMgr().Init();

	/* Init ZCL Data Model and start server */
	chip::Server::GetInstance().Init();

	/* Initialize device attestation config */
	SetDeviceAttestationCredentialsProvider(Examples::GetExampleDACProvider());
	ConfigurationMgr().LogDeviceConfig();
	PrintOnboardingCodes(chip::RendezvousInformationFlags(chip::RendezvousInformationFlag::kBLE));

	PlatformMgr().AddEventHandler(AppTask::ChipEventHandler, 0);

#ifdef CONFIG_CHIP_OTA_REQUESTOR
	sOTAImageProcessor.SetOTADownloader(&sBDXDownloader);
	sBDXDownloader.SetImageProcessorDelegate(&sOTAImageProcessor);
	sOTARequestorDriver.Init(&sOTARequestor, &sOTAImageProcessor);
	sOTARequestor.Init(&chip::Server::GetInstance(), &sOTARequestorDriver, &sBDXDownloader);
	chip::SetRequestorInstance(&sOTARequestor);
#endif

	return 0;
}

int AppTask::StartApp()
{
	int ret = Init();

	if (ret) {
		LOG_ERR("AppTask.Init() failed");
		return ret;
	}

	AppEvent event = {};

	while (true) {
		k_msgq_get(&sAppEventQueue, &event, K_FOREVER);
		DispatchEvent(event);
	}
}

void AppTask::PostEvent(const AppEvent &event)
{
	if (k_msgq_put(&sAppEventQueue, &event, K_NO_WAIT)) {
		LOG_INF("Failed to post event to app task event queue");
	}
}

void AppTask::UpdateClusterState()
{
	/* write the new on/off value */
	EmberAfStatus status = Clusters::OnOff::Attributes::OnOff::Set(kLockEndpointId, !BoltLockMgr().IsUnlocked());

	if (status != EMBER_ZCL_STATUS_SUCCESS) {
		LOG_ERR("Updating on/off cluster failed: %x", status);
	}
}

#ifdef CONFIG_MCUMGR_SMP_BT
void AppTask::RequestSMPAdvertisingStart(void)
{
	sAppTask.PostEvent(AppEvent{ AppEvent::StartSMPAdvertising });
}
#endif

void AppTask::DispatchEvent(const AppEvent &event)
{
	switch (event.Type) {
	case AppEvent::Lock:
		LockActionHandler(BoltLockManager::Action::Lock, event.LockEvent.ChipInitiated);
		break;
	case AppEvent::Unlock:
		LockActionHandler(BoltLockManager::Action::Unlock, event.LockEvent.ChipInitiated);
		break;
	case AppEvent::Toggle:
		LockActionHandler(BoltLockMgr().IsUnlocked() ? BoltLockManager::Action::Lock :
								     BoltLockManager::Action::Unlock,
				  event.LockEvent.ChipInitiated);
		break;
	case AppEvent::CompleteLockAction:
		CompleteLockActionHandler();
		break;
	case AppEvent::FunctionPress:
		FunctionPressHandler();
		break;
	case AppEvent::FunctionRelease:
		FunctionReleaseHandler();
		break;
	case AppEvent::FunctionTimer:
		FunctionTimerEventHandler();
		break;
	case AppEvent::StartThread:
		StartThreadHandler();
		break;
	case AppEvent::StartBleAdvertising:
		StartBLEAdvertisingHandler();
		break;
	case AppEvent::UpdateLedState:
		event.UpdateLedStateEvent.LedWidget->UpdateState();
		break;
#ifdef CONFIG_MCUMGR_SMP_BT
	case AppEvent::StartSMPAdvertising:
		GetDFUOverSMP().StartBLEAdvertising();
		break;
#endif
	default:
		LOG_INF("Unknown event received");
		break;
	}
}

void AppTask::LockActionHandler(BoltLockManager::Action action, bool chipInitiated)
{
	if (BoltLockMgr().InitiateAction(action, chipInitiated)) {
		sLockLED.Blink(50, 50);
	}
}

void AppTask::CompleteLockActionHandler()
{
	bool chipInitiatedAction;

	if (!BoltLockMgr().CompleteCurrentAction(chipInitiatedAction)) {
		return;
	}

	sLockLED.Set(!BoltLockMgr().IsUnlocked());

	/* If the action wasn't initiated by CHIP, update CHIP clusters with the new lock state */
	if (!chipInitiatedAction) {
		UpdateClusterState();
	}
}

void AppTask::FunctionPressHandler()
{
	sAppTask.StartFunctionTimer(kFactoryResetTriggerTimeout);
	sAppTask.mFunction = TimerFunction::SoftwareUpdate;
}

void AppTask::FunctionReleaseHandler()
{
	if (sAppTask.mFunction == TimerFunction::SoftwareUpdate) {
		sAppTask.CancelFunctionTimer();
		sAppTask.mFunction = TimerFunction::NoneSelected;

#ifdef CONFIG_MCUMGR_SMP_BT
		GetDFUOverSMP().StartServer();
#else
		LOG_INF("Software update is disabled");
#endif

	} else if (sAppTask.mFunction == TimerFunction::FactoryReset) {
		sUnusedLED_1.Set(false);
		sUnusedLED.Set(false);

		/* Set lock status LED back to show state of lock. */
		sLockLED.Set(!BoltLockMgr().IsUnlocked());

		UpdateStatusLED();

		sAppTask.CancelFunctionTimer();
		sAppTask.mFunction = TimerFunction::NoneSelected;
		LOG_INF("Factory Reset has been Canceled");
	}
}

void AppTask::FunctionTimerEventHandler()
{
	if (sAppTask.mFunction == TimerFunction::SoftwareUpdate) {
		LOG_INF("Factory Reset Triggered. Release button within %ums to cancel.", kFactoryResetCancelWindow);
		sAppTask.StartFunctionTimer(kFactoryResetCancelWindow);
		sAppTask.mFunction = TimerFunction::FactoryReset;

#ifdef CONFIG_STATE_LEDS
		/* Turn off all LEDs before starting blink to make sure blink is co-ordinated. */
		sStatusLED.Set(false);
		sLockLED.Set(false);
		sUnusedLED_1.Set(false);
		sUnusedLED.Set(false);

		sStatusLED.Blink(500);
		sLockLED.Blink(500);
		sUnusedLED.Blink(500);
		sUnusedLED_1.Blink(500);
#endif
	} else if (sAppTask.mFunction == TimerFunction::FactoryReset) {
		sAppTask.mFunction = TimerFunction::NoneSelected;
		LOG_INF("Factory Reset triggered");
		ConfigurationMgr().InitiateFactoryReset();
	}
}

void AppTask::StartThreadHandler()
{
	if (chip::Server::GetInstance().AddTestCommissioning() != CHIP_NO_ERROR) {
		LOG_ERR("Failed to add test pairing");
	}

	if (!ConnectivityMgr().IsThreadProvisioned()) {
		StartDefaultThreadNetwork();
		LOG_INF("Device is not commissioned to a Thread network. Starting with the default configuration");
	} else {
		LOG_INF("Device is commissioned to a Thread network");
	}
}

void AppTask::StartBLEAdvertisingHandler()
{
	/* Don't allow on starting Matter service BLE advertising after Thread provisioning. */
	if (ConnectivityMgr().IsThreadProvisioned()) {
		LOG_INF("NFC Tag emulation and Matter service BLE advertising not started - device is commissioned to a Thread network.");
		return;
	}

	if (ConnectivityMgr().IsBLEAdvertisingEnabled()) {
		LOG_INF("BLE advertising is already enabled");
		return;
	}

	if (chip::Server::GetInstance().GetCommissioningWindowManager().OpenBasicCommissioningWindow() !=
	    CHIP_NO_ERROR) {
		LOG_ERR("OpenBasicCommissioningWindow() failed");
	}
}

void AppTask::LEDStateUpdateHandler(LEDWidget &ledWidget)
{
	sAppTask.PostEvent(AppEvent{ AppEvent::UpdateLedState, &ledWidget });
}

void AppTask::UpdateStatusLED()
{
#ifdef CONFIG_STATE_LEDS
	/* Update the status LED.
	 *
	 * If thread and service provisioned, keep the LED On constantly.
	 *
	 * If the system has ble connection(s) uptill the stage above, THEN blink the LED at an even
	 * rate of 100ms.
	 *
	 * Otherwise, blink the LED On for a very short time. */
	if (sIsThreadProvisioned && sIsThreadEnabled) {
		sStatusLED.Set(true);
	} else if (sHaveBLEConnections) {
		sStatusLED.Blink(100, 100);
	} else {
		sStatusLED.Blink(50, 950);
	}
#endif
}

void AppTask::ChipEventHandler(const ChipDeviceEvent *event, intptr_t /* arg */)
{
	switch (event->Type) {
	case DeviceEventType::kCHIPoBLEAdvertisingChange:
#ifdef CONFIG_CHIP_NFC_COMMISSIONING
		if (event->CHIPoBLEAdvertisingChange.Result == kActivity_Started) {
			if (NFCMgr().IsTagEmulationStarted()) {
				LOG_INF("NFC Tag emulation is already started");
			} else {
				ShareQRCodeOverNFC(
					chip::RendezvousInformationFlags(chip::RendezvousInformationFlag::kBLE));
			}
		} else if (event->CHIPoBLEAdvertisingChange.Result == kActivity_Stopped) {
			NFCMgr().StopTagEmulation();
		}
#endif
		sHaveBLEConnections = ConnectivityMgr().NumBLEConnections() != 0;
		UpdateStatusLED();
		break;
	case DeviceEventType::kThreadStateChange:
		sIsThreadProvisioned = ConnectivityMgr().IsThreadProvisioned();
		sIsThreadEnabled = ConnectivityMgr().IsThreadEnabled();
		UpdateStatusLED();
		break;
	default:
		break;
	}
}

void AppTask::ButtonEventHandler(uint32_t buttonState, uint32_t hasChanged)
{
	if (DK_BTN1_MSK & buttonState & hasChanged) {
		GetAppTask().PostEvent(AppEvent{ AppEvent::FunctionPress });
	} else if (DK_BTN1_MSK & hasChanged) {
		GetAppTask().PostEvent(AppEvent{ AppEvent::FunctionRelease });
	}

	if (DK_BTN2_MSK & buttonState & hasChanged) {
		GetAppTask().PostEvent(AppEvent{ AppEvent::Toggle, false });
	}

	if (DK_BTN3_MSK & buttonState & hasChanged) {
		GetAppTask().PostEvent(AppEvent{ AppEvent::StartThread });
	}

	if (DK_BTN4_MSK & buttonState & hasChanged) {
		GetAppTask().PostEvent(AppEvent{ AppEvent::StartBleAdvertising });
	}
}

void AppTask::CancelFunctionTimer()
{
	k_timer_stop(&sFunctionTimer);
}

void AppTask::StartFunctionTimer(uint32_t timeoutInMs)
{
	k_timer_start(&sFunctionTimer, K_MSEC(timeoutInMs), K_NO_WAIT);
}

void AppTask::TimerEventHandler(k_timer *timer)
{
	GetAppTask().PostEvent(AppEvent{ AppEvent::FunctionTimer });
}
```

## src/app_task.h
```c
/*
 * Copyright (c) 2021 Nordic Semiconductor ASA
 *
 * SPDX-License-Identifier: LicenseRef-Nordic-5-Clause
 */

#pragma once

#include "app_event.h"
#include "bolt_lock_manager.h"
#include "led_widget.h"

#include <platform/CHIPDeviceLayer.h>

#ifdef CONFIG_MCUMGR_SMP_BT
#include "dfu_over_smp.h"
#endif

struct k_timer;

class AppTask {
public:
	int StartApp();

	void PostEvent(const AppEvent &aEvent);
	void UpdateClusterState();

private:
	int Init();

	void CancelFunctionTimer();
	void StartFunctionTimer(uint32_t timeoutInMs);

	void DispatchEvent(const AppEvent &event);
	void LockActionHandler(BoltLockManager::Action action, bool chipInitiated);
	void CompleteLockActionHandler();
	void FunctionPressHandler();
	void FunctionReleaseHandler();
	void FunctionTimerEventHandler();
	void StartThreadHandler();
	void StartBLEAdvertisingHandler();

	static void UpdateStatusLED();
	static void ButtonEventHandler(uint32_t buttonState, uint32_t hasChanged);
	static void TimerEventHandler(k_timer *timer);
	static void LEDStateUpdateHandler(LEDWidget &ledWidget);
	static void ChipEventHandler(const chip::DeviceLayer::ChipDeviceEvent *event, intptr_t arg);
#ifdef CONFIG_MCUMGR_SMP_BT
	static void RequestSMPAdvertisingStart(void);
#endif

	friend AppTask &GetAppTask();

	enum class TimerFunction { NoneSelected = 0, SoftwareUpdate, FactoryReset };

	TimerFunction mFunction = TimerFunction::NoneSelected;

	static AppTask sAppTask;
	bool mFunctionTimerActive = false;
};

inline AppTask &GetAppTask()
{
	return AppTask::sAppTask;
}
```

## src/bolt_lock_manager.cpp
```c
/*
 * Copyright (c) 2021 Nordic Semiconductor ASA
 *
 * SPDX-License-Identifier: LicenseRef-Nordic-5-Clause
 */

#include "bolt_lock_manager.h"

#include "app_task.h"

#include <logging/log.h>
#include <zephyr.h>

LOG_MODULE_DECLARE(app);

static k_timer sLockTimer;

BoltLockManager BoltLockManager::sLock;

void BoltLockManager::Init()
{
	k_timer_init(&sLockTimer, &BoltLockManager::ActuatorTimerHandler, nullptr);
	k_timer_user_data_set(&sLockTimer, this);

	mState = State::LockingCompleted;
	mChipInitiatedAction = false;
}

bool BoltLockManager::IsActionInProgress()
{
	return mState == State::LockingInitiated || mState == State::UnlockingInitiated;
}

bool BoltLockManager::IsUnlocked()
{
	return mState == State::UnlockingCompleted;
}

bool BoltLockManager::InitiateAction(Action action, bool chipInitiated)
{
	/* Initiate Lock/Unlock Action only when the previous one is complete. */
	switch (action) {
	case Action::Lock:
		if (mState != State::UnlockingCompleted) {
			return false;
		}
		LOG_INF("Lock Action has been initiated");
		mState = State::LockingInitiated;
		break;
	case Action::Unlock:
		if (mState != State::LockingCompleted) {
			return false;
		}
		LOG_INF("Unlock Action has been initiated");
		mState = State::UnlockingInitiated;
		break;
	default:
		return false;
	}

	mChipInitiatedAction = chipInitiated;
	StartTimer(kActuatorMovementPeriodMs);
	return true;
}

bool BoltLockManager::CompleteCurrentAction(bool &chipInitiated)
{
	switch (mState) {
	case State::LockingInitiated:
		LOG_INF("Lock Action has been completed");
		mState = State::LockingCompleted;
		chipInitiated = mChipInitiatedAction;
		return true;
	case State::UnlockingInitiated:
		LOG_INF("Unlock Action has been completed");
		mState = State::UnlockingCompleted;
		chipInitiated = mChipInitiatedAction;
		return true;
	default:
		return false;
	}
}

void BoltLockManager::StartTimer(uint32_t aTimeoutMs)
{
	k_timer_start(&sLockTimer, K_MSEC(aTimeoutMs), K_NO_WAIT);
}

void BoltLockManager::CancelTimer()
{
	k_timer_stop(&sLockTimer);
}

void BoltLockManager::ActuatorTimerHandler(k_timer *timer)
{
	GetAppTask().PostEvent(AppEvent{ AppEvent::CompleteLockAction, false });
}
```

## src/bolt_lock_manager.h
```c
/*
 * Copyright (c) 2021 Nordic Semiconductor ASA
 *
 * SPDX-License-Identifier: LicenseRef-Nordic-5-Clause
 */

#pragma once

#include <cstdint>

#include "app_event.h"

struct k_timer;

class BoltLockManager {
public:
	enum class Action : uint8_t { Lock, Unlock };

	void Init();

	bool IsUnlocked();
	bool IsActionInProgress();

	bool InitiateAction(Action action, bool chipInitiated);
	bool CompleteCurrentAction(bool &chipInitiated);

private:
	enum class State : uint8_t { LockingInitiated = 0, LockingCompleted, UnlockingInitiated, UnlockingCompleted };

	static constexpr uint32_t kActuatorMovementPeriodMs = 2000;

	void StartTimer(uint32_t aTimeoutMs);
	void CancelTimer();

	static void ActuatorTimerHandler(k_timer *timer);

	friend BoltLockManager &BoltLockMgr();

	State mState;
	bool mChipInitiatedAction;

	static BoltLockManager sLock;
};

inline BoltLockManager &BoltLockMgr()
{
	return BoltLockManager::sLock;
}
```

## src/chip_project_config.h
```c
/*
 * Copyright (c) 2021 Nordic Semiconductor ASA
 *
 * SPDX-License-Identifier: LicenseRef-Nordic-5-Clause
 */

/**
 *    @file
 *          Example project configuration file for CHIP.
 *
 *          This is a place to put application or project-specific overrides
 *          to the default configuration values for general CHIP features.
 *
 */

#pragma once

/**
 * CHIP_DEVICE_CONFIG_DEVICE_PRODUCT_ID
 *
 * 0x4E4B: nrfconnect lock
 */
#define CHIP_DEVICE_CONFIG_DEVICE_PRODUCT_ID 0x4E4B

/* Use a default pairing code if one hasn't been provisioned in flash. */
#define CHIP_DEVICE_CONFIG_USE_TEST_SETUP_PIN_CODE 20202021
#define CHIP_DEVICE_CONFIG_USE_TEST_SETUP_DISCRIMINATOR 0xF00

#define CHIP_DEVICE_CONFIG_SED_SLOW_POLLING_INTERVAL 2000_ms32
```

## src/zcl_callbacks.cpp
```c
/*
 * Copyright (c) 2021 Nordic Semiconductor ASA
 *
 * SPDX-License-Identifier: LicenseRef-Nordic-5-Clause
 */

#include <lib/support/logging/CHIPLogging.h>

#include "app_task.h"
#include "bolt_lock_manager.h"

#include <app-common/zap-generated/ids/Attributes.h>
#include <app-common/zap-generated/ids/Clusters.h>
#include <app/ConcreteAttributePath.h>

using namespace ::chip;
using namespace ::chip::app::Clusters;

void MatterPostAttributeChangeCallback(const chip::app::ConcreteAttributePath &attributePath, uint8_t mask,
				       uint8_t type, uint16_t size, uint8_t *value)
{
	if (attributePath.mClusterId == OnOff::Id && attributePath.mAttributeId == OnOff::Attributes::OnOff::Id) {
		ChipLogProgress(Zcl, "Cluster OnOff: attribute OnOff set to %" PRIu8, *value);
		GetAppTask().PostEvent(AppEvent(*value ? AppEvent::Lock : AppEvent::Unlock, true));
	}
}

/** @brief OnOff Cluster Init
 *
 * This function is called when a specific cluster is initialized. It gives the
 * application an opportunity to take care of cluster initialization procedures.
 * It is called exactly once for each endpoint where cluster is present.
 *
 * @param endpoint   Ver.: always
 *
 * TODO Issue #3841
 * emberAfOnOffClusterInitCallback happens before the stack initialize the cluster
 * attributes to the default value.
 * The logic here expects something similar to the deprecated Plugins callback
 * emberAfPluginOnOffClusterServerPostInitCallback.
 *
 */
void emberAfOnOffClusterInitCallback(EndpointId endpoint)
{
	GetAppTask().UpdateClusterState();
}
```
